# M02_SRAM register map
Vendor: Babel; File version: 1.0
M02_SRAM Register Map
CPU: CM0 r0p0, little endian, no MPU, no FPU
Registers are 32-bit, read-only, reset 0x0 unless marked. A register's access mark holds for its fields unless they carry their own. Offsets are from the block's base; lines under a group give offsets from that group; [hi:lo] are bit positions; {n}, {i} and the like mark numbered series; 'fields as' and 'values as' point back to an identical list; <NAME> marks a mode.

## Memory map
0x00000000 M02_SRAM

## M02_SRAM
Base 0x00000000
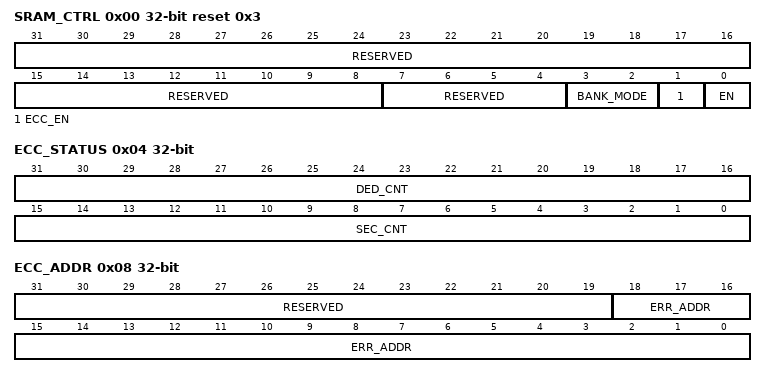
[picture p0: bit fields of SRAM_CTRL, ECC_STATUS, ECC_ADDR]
0x00 SRAM_CTRL rw reset 0x3 — 控制寄存器：使能、ECC、Bank 模式
  [31:8] RESERVED - — 保留，必须写 0
  [7:4] RESERVED - — 保留，必须写 0
  [3:2] BANK_MODE — Bank 模式。00=独立，01=交织
  [1] ECC_EN — ECC 使能。1=使能，0=禁用
  [0] EN — SRAM 使能。1=使能，0=禁用
0x04 ECC_STATUS — ECC 错误统计：SEC/DED 计数
  [31:16] DED_CNT — 双比特检测累计计数
  [15:0] SEC_CNT — 单比特纠正累计计数
0x08 ECC_ADDR — 最近 ECC 错误地址
  [31:19] RESERVED - — 保留
  [18:0] ERR_ADDR — 最近 ECC 错误地址（19-bit 字地址）
